# RN8XXX_V2 register map
File version: 1.0
Registers are 32-bit, read-write, reset 0x0 unless marked. A register's access mark holds for its fields unless they carry their own. Offsets are from the block's base; [hi:lo] are bit positions.

## analog — analog peripherals
Base 0x4002C000
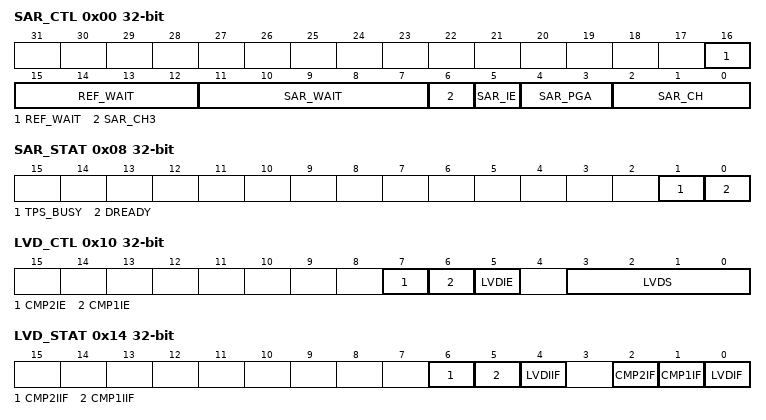
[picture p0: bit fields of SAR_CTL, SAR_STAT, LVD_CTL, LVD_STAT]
0x00 SAR_CTL — SAR ADC control,writable only bitfield ST of register ADC_START is 0
  [16:12] REF_WAIT — voltage reference setup duration ((REF_WAIT+1)*30.5us) between enable and ADC enable
  [11:7] SAR_WAIT — SAR ADC setup duration ((SAR_WAIT+1)*30.5us) between enable and sample
  [6] SAR_CH3 — SAR ADC channel selection
    0=no_action (ADC channel is selected by SAR_CH); 1=SAR_CH3 (commbid with SAR_CH to select ADC channel)
  [5] SAR_IE — SAR ADC interrupt enable
    0=disable (do not generate interrupt request on SAR event); 1=enable (generate interrupt request on SAR event)
  [4:3] SAR_PGA — SAR ADC gain
    0=0.5x (use 0.5 gain factor); 1=use 1 gain factor; 2=1.5x (use 1.5 gain factor); 3=2x (use 2 gain factor)
  [2:0] SAR_CH — SAR ADC channel selection
    0=TempSensor (select temperature sensor output as input of SAR); 1=VBAT/2 (select 1/2 of battery voltage as input of SAR); 2=VIN0 (select voltage input No.0 as input of SAR); 3=VIN1 (select voltage input No.1 as input of SAR); 4=VIN2 (select voltage input No.2 as input of SAR); 5=VIN3 (select voltage input No.3 as input of SAR); 6=VIN4 (select voltage input No.4 as input of SAR); 7=VIN5 (select voltage input No.5 as input of SAR)
0x04 SAR_START — SAR ADC start control
  [0] ST — SAR ADC start bit
    0=no_action (stop SAR ADC); 1=start SAR ADC
0x08 SAR_STAT — SAR ADC status
  [1] TPS_BUSY ro — automatic temperature measurement busy
    0=idle (no outstanding automatic temperature measurement); 1=busy (pending automatic temperature measurement,ADC_START is not writable)
  [0] DREADY write-1-clears — SAR ADC data ready pending
    0=not_pending (no outstanding SAR ADC completed); 1=pending (last SAR ADC completed)
0x0C SAR_DAT — SAR ADC result
  [9:0] DAT ro
0x10 LVD_CTL — LVD control
  [7] CMP2IE — comparator No.2 interrupt enable
    0=disable (do not generate interrupt request on comparator No.2 event); 1=enable (generate interrupt request on comparator No.2 event)
  [6] CMP1IE — comparator No.1 interrupt enable
    0=disable (do not generate interrupt request on comparator No.1 event); 1=enable (generate interrupt request on comparator No.1 event)
  [5] LVDIE — LVD interrupt enable
    0=disable (do not generate interrupt request on LVD event); 1=enable (generate interrupt request on LVD event)
  [3:0] LVDS — LVD threshold voltage setting
    0=2.3v (LVD threshold voltage set as 2.3v); 1=2.5v (LVD threshold voltage set as 2.5v); 2=2.7v (LVD threshold voltage set as 2.7v); 3=2.9v (LVD threshold voltage set as 2.9v); 4=3.1v (LVD threshold voltage set as 3.1v); 5=3.3v (LVD threshold voltage set as 3.3v); 6=3.5v (LVD threshold voltage set as 3.5v); 7=3.7v (LVD threshold voltage set as 3.7v); 8=3.9v (LVD threshold voltage set as 3.9v); 9=4.1v (LVD threshold voltage set as 4.1v); 10=4.3v (LVD threshold voltage set as 4.3v); 11=4.5v (LVD threshold voltage set as 4.5v); 12=4.7v (LVD threshold voltage set as 4.7v); 13=4.8v (LVD threshold voltage set as 4.8v); 14=LVDIN0 (LVD threshold voltage set as 1.25v,and compare with voltage found on LVDIN0 pin)
0x14 LVD_STAT — LVD status
  [6] CMP2IIF write-1-clears — comparator No.2 interrupt flag
    0=not_pending (no outstanding comparator NO.2 event found); 1=pending comparator NO.2 event
  [5] CMP1IIF write-1-clears — comparator NO.1 interrupt flag
    0=not_pending (no outstanding comparator NO.1 event found); 1=pending comparator NO.1 event
  [4] LVDIIF write-1-clears — LVD interrupt flag
    0=not_pending (no outstanding LVD event found); 1=pending LVD event
  [2] CMP2IF ro — comparator No.2 status
    0=lower than threshold; 1=higher than threshold
  [1] CMP1IF ro — comparator NO.1 status
    0=lower than threshold; 1=higher than threshold
  [0] LVDIF ro — LVD status
    0=lower than threshold; 1=higher than threshold
0x1C SAR_DAT2 — SAR ADC result
  [11:0] SAR_ADC_DAT2 ro — 12 bits result
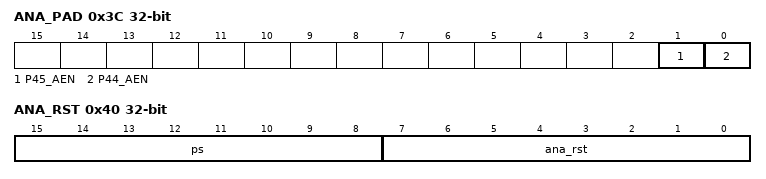
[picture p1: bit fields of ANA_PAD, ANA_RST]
0x3C ANA_PAD — Analog input selection
  [1] P45_AEN — Enable analog input on P45
    0=Disable analog input of P45; 1=Enable analog input of P45
  [0] P44_AEN — Enable analog input on P44
    0=Disable analog input of P44; 1=Enable analog input of P44
0x40 ANA_RST — Analog input selection
  [15:8] ps ro — Password for low 8 bits of this registers
  [7:0] ana_rst ro — Reset registers in VBAT area
